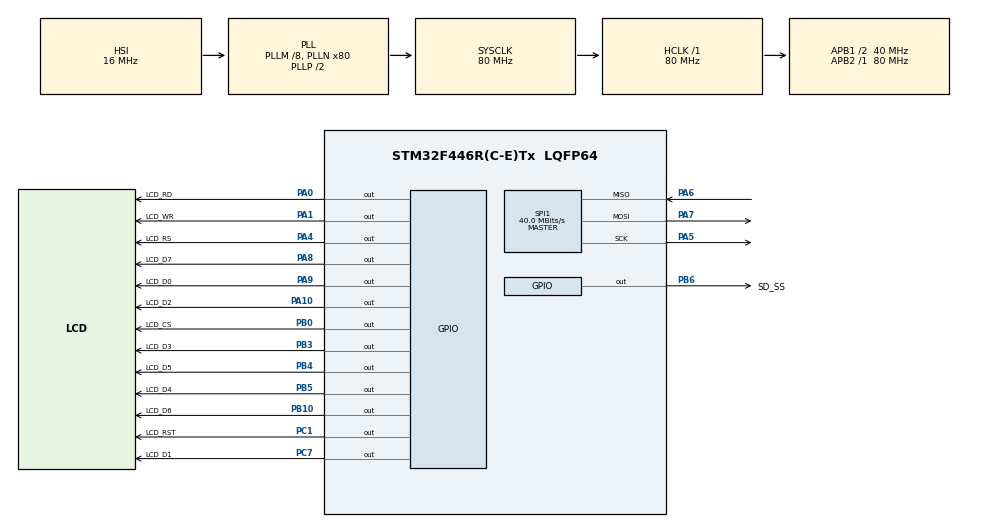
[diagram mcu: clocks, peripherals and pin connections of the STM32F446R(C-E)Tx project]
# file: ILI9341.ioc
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Mcu.Family=STM32F4
Mcu.Name=STM32F446R(C-E)Tx
Mcu.Package=LQFP64
NVIC.PriorityGroup=NVIC_PRIORITYGROUP_4
PA0-WKUP.GPIO_Label=LCD_RD
PA0-WKUP.GPIO_Speed=GPIO_SPEED_FREQ_HIGH
PA0-WKUP.Signal=GPIO_Output
PA1.GPIO_Label=LCD_WR
PA1.GPIO_Speed=GPIO_SPEED_FREQ_HIGH
PA1.Signal=GPIO_Output
PA10.GPIO_Label=LCD_D2
PA10.GPIO_Speed=GPIO_SPEED_FREQ_HIGH
PA10.Signal=GPIO_Output
PA13.Mode=Serial_Wire
PA13.Signal=SYS_JTMS-SWDIO
PA14.Mode=Serial_Wire
PA14.Signal=SYS_JTCK-SWCLK
PA4.GPIO_Label=LCD_RS
PA4.GPIO_Speed=GPIO_SPEED_FREQ_HIGH
PA4.Signal=GPIO_Output
PA5.Mode=Full_Duplex_Master
PA5.Signal=SPI1_SCK
PA6.Mode=Full_Duplex_Master
PA6.Signal=SPI1_MISO
PA7.Mode=Full_Duplex_Master
PA7.Signal=SPI1_MOSI
PA8.GPIO_Label=LCD_D7
PA8.GPIO_Speed=GPIO_SPEED_FREQ_HIGH
PA8.Signal=GPIO_Output
PA9.GPIO_Label=LCD_D0
PA9.GPIO_Speed=GPIO_SPEED_FREQ_HIGH
PA9.Signal=GPIO_Output
PB0.GPIO_Label=LCD_CS
PB0.GPIO_Speed=GPIO_SPEED_FREQ_HIGH
PB0.Signal=GPIO_Output
PB10.GPIO_Label=LCD_D6
PB10.GPIO_Speed=GPIO_SPEED_FREQ_HIGH
PB10.Signal=GPIO_Output
PB3.GPIO_Label=LCD_D3
PB3.GPIO_Speed=GPIO_SPEED_FREQ_HIGH
PB3.Signal=GPIO_Output
PB4.GPIO_Label=LCD_D5
PB4.GPIO_Speed=GPIO_SPEED_FREQ_HIGH
PB4.Signal=GPIO_Output
PB5.GPIO_Label=LCD_D4
PB5.GPIO_Speed=GPIO_SPEED_FREQ_HIGH
PB5.Signal=GPIO_Output
PB6.GPIO_Label=SD_SS
PB6.GPIO_Speed=GPIO_SPEED_FREQ_HIGH
PB6.Signal=GPIO_Output
PC1.GPIO_Label=LCD_RST
PC1.GPIO_Speed=GPIO_SPEED_FREQ_HIGH
PC1.Signal=GPIO_Output
PC7.GPIO_Label=LCD_D1
PC7.GPIO_Speed=GPIO_SPEED_FREQ_HIGH
PC7.Signal=GPIO_Output
PH0-OSC_IN.Mode=HSE-External-Oscillator
PH0-OSC_IN.Signal=RCC_OSC_IN
PH1-OSC_OUT.Mode=HSE-External-Oscillator
PH1-OSC_OUT.Signal=RCC_OSC_OUT
ProjectManager.HeapSize=0x200
ProjectManager.StackSize=0x400
ProjectManager.TargetToolchain=STM32CubeIDE
RCC.AHBFreq_Value=80000000
RCC.APB1CLKDivider=RCC_HCLK_DIV2
RCC.APB1Freq_Value=40000000
RCC.APB1TimFreq_Value=80000000
RCC.APB2Freq_Value=80000000
RCC.APB2TimFreq_Value=80000000
RCC.CortexFreq_Value=80000000
RCC.HCLKFreq_Value=80000000
RCC.PLLM=8
RCC.PLLN=80
RCC.SYSCLKFreq_VALUE=80000000
RCC.SYSCLKSource=RCC_SYSCLKSOURCE_PLLCLK
RCC.USBFreq_Value=80000000
RCC.VCOOutputFreq_Value=160000000
SPI1.CalculateBaudRate=40.0 MBits/s
SPI1.Direction=SPI_DIRECTION_2LINES
SPI1.Mode=SPI_MODE_MASTER
SPI1.VirtualType=VM_MASTER
board=custom

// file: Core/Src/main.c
/* USER CODE BEGIN Header */
/**
 ******************************************************************************
 * @file           : main.c
 * @brief          : Main program body
 ******************************************************************************
 * @attention
 *
 * Copyright (c) 2024 STMicroelectronics.
 * All rights reserved.
 *
 * This software is licensed under terms that can be found in the LICENSE file
 * in the root directory of this software component.
 * If no LICENSE file comes with this software, it is provided AS-IS.
 *
 ******************************************************************************
 */
/* USER CODE END Header */
#include "main.h"

/* USER CODE BEGIN Includes */
#include "ili9341.h"
/* USER CODE END Includes */

SPI_HandleTypeDef hspi1;
/* USER CODE BEGIN PV */
extern uint8_t fondo[];
/* USER CODE END PV */

void SystemClock_Config(void);
static void MX_GPIO_Init(void);
static void MX_SPI1_Init(void);

int main(void)
{

  /* MCU Configuration--------------------------------------------------------*/

  /* Reset of all peripherals, Initializes the Flash interface and the Systick. */
  HAL_Init();

  /* Configure the system clock */
  SystemClock_Config();

  /* Initialize all configured peripherals */
  MX_GPIO_Init();
  MX_SPI1_Init();
  /* USER CODE BEGIN 2 */

	LCD_Init();

	LCD_Clear(0x00);
	FillRect(0, 0, 319, 239, 0xFFFF);
	FillRect(50, 60, 20, 20, 0xF800);
	FillRect(70, 60, 20, 20, 0x07E0);
	FillRect(90, 60, 20, 20, 0x001F);

	//LCD_Bitmap(0, 0, 320, 240, fondo);
	 FillRect(0, 0, 319, 206, 0x1911);

	  LCD_Print("Hola Mundo", 20, 100, 1, 0x001F, 0xCAB9);

  /* USER CODE END 2 */

  /* Infinite loop */
	while (1) {

	}
}

void SystemClock_Config(void)
{
  RCC_OscInitTypeDef RCC_OscInitStruct = {0};
  RCC_ClkInitTypeDef RCC_ClkInitStruct = {0};

  /** Configure the main internal regulator output voltage
  */
  __HAL_RCC_PWR_CLK_ENABLE();
  __HAL_PWR_VOLTAGESCALING_CONFIG(PWR_REGULATOR_VOLTAGE_SCALE3);

  /** Initializes the RCC Oscillators according to the specified parameters
  * in the RCC_OscInitTypeDef structure.
  */
  RCC_OscInitStruct.OscillatorType = RCC_OSCILLATORTYPE_HSI;
  RCC_OscInitStruct.HSIState = RCC_HSI_ON;
  RCC_OscInitStruct.HSICalibrationValue = RCC_HSICALIBRATION_DEFAULT;
  RCC_OscInitStruct.PLL.PLLState = RCC_PLL_ON;
  RCC_OscInitStruct.PLL.PLLSource = RCC_PLLSOURCE_HSI;
  RCC_OscInitStruct.PLL.PLLM = 8;
  RCC_OscInitStruct.PLL.PLLN = 80;
  RCC_OscInitStruct.PLL.PLLP = RCC_PLLP_DIV2;
  RCC_OscInitStruct.PLL.PLLQ = 2;
  RCC_OscInitStruct.PLL.PLLR = 2;
  if (HAL_RCC_OscConfig(&RCC_OscInitStruct) != HAL_OK)
  {
    Error_Handler();
  }

  /** Initializes the CPU, AHB and APB buses clocks
  */
  RCC_ClkInitStruct.ClockType = RCC_CLOCKTYPE_HCLK|RCC_CLOCKTYPE_SYSCLK
                              |RCC_CLOCKTYPE_PCLK1|RCC_CLOCKTYPE_PCLK2;
  RCC_ClkInitStruct.SYSCLKSource = RCC_SYSCLKSOURCE_PLLCLK;
  RCC_ClkInitStruct.AHBCLKDivider = RCC_SYSCLK_DIV1;
  RCC_ClkInitStruct.APB1CLKDivider = RCC_HCLK_DIV2;
  RCC_ClkInitStruct.APB2CLKDivider = RCC_HCLK_DIV1;

  if (HAL_RCC_ClockConfig(&RCC_ClkInitStruct, FLASH_LATENCY_2) != HAL_OK)
  {
    Error_Handler();
  }
}

static void MX_SPI1_Init(void)
{

  /* SPI1 parameter configuration*/
  hspi1.Instance = SPI1;
  hspi1.Init.Mode = SPI_MODE_MASTER;
  hspi1.Init.Direction = SPI_DIRECTION_2LINES;
  hspi1.Init.DataSize = SPI_DATASIZE_8BIT;
  hspi1.Init.CLKPolarity = SPI_POLARITY_LOW;
  hspi1.Init.CLKPhase = SPI_PHASE_1EDGE;
  hspi1.Init.NSS = SPI_NSS_SOFT;
  hspi1.Init.BaudRatePrescaler = SPI_BAUDRATEPRESCALER_2;
  hspi1.Init.FirstBit = SPI_FIRSTBIT_MSB;
  hspi1.Init.TIMode = SPI_TIMODE_DISABLE;
  hspi1.Init.CRCCalculation = SPI_CRCCALCULATION_DISABLE;
  hspi1.Init.CRCPolynomial = 10;
  if (HAL_SPI_Init(&hspi1) != HAL_OK)
  {
    Error_Handler();
  }

}

static void MX_GPIO_Init(void)
{
  GPIO_InitTypeDef GPIO_InitStruct = {0};

  /* GPIO Ports Clock Enable */
  __HAL_RCC_GPIOH_CLK_ENABLE();
  __HAL_RCC_GPIOC_CLK_ENABLE();
  __HAL_RCC_GPIOA_CLK_ENABLE();
  __HAL_RCC_GPIOB_CLK_ENABLE();

  /*Configure GPIO pin Output Level */
  HAL_GPIO_WritePin(GPIOC, LCD_RST_Pin|LCD_D1_Pin, GPIO_PIN_RESET);

  /*Configure GPIO pin Output Level */
  HAL_GPIO_WritePin(GPIOA, LCD_RD_Pin|LCD_WR_Pin|LCD_RS_Pin|LCD_D7_Pin
                          |LCD_D0_Pin|LCD_D2_Pin, GPIO_PIN_RESET);

  /*Configure GPIO pin Output Level */
  HAL_GPIO_WritePin(GPIOB, LCD_CS_Pin|LCD_D6_Pin|LCD_D3_Pin|LCD_D5_Pin
                          |LCD_D4_Pin|SD_SS_Pin, GPIO_PIN_RESET);

  /*Configure GPIO pins : LCD_RST_Pin LCD_D1_Pin */
  GPIO_InitStruct.Pin = LCD_RST_Pin|LCD_D1_Pin;
  GPIO_InitStruct.Mode = GPIO_MODE_OUTPUT_PP;
  GPIO_InitStruct.Pull = GPIO_NOPULL;
  GPIO_InitStruct.Speed = GPIO_SPEED_FREQ_HIGH;
  HAL_GPIO_Init(GPIOC, &GPIO_InitStruct);

  /*Configure GPIO pins : LCD_RD_Pin LCD_WR_Pin LCD_RS_Pin LCD_D7_Pin
                           LCD_D0_Pin LCD_D2_Pin */
  GPIO_InitStruct.Pin = LCD_RD_Pin|LCD_WR_Pin|LCD_RS_Pin|LCD_D7_Pin
                          |LCD_D0_Pin|LCD_D2_Pin;
  GPIO_InitStruct.Mode = GPIO_MODE_OUTPUT_PP;
  GPIO_InitStruct.Pull = GPIO_NOPULL;
  GPIO_InitStruct.Speed = GPIO_SPEED_FREQ_HIGH;
  HAL_GPIO_Init(GPIOA, &GPIO_InitStruct);

  /*Configure GPIO pins : LCD_CS_Pin LCD_D6_Pin LCD_D3_Pin LCD_D5_Pin
                           LCD_D4_Pin SD_SS_Pin */
  GPIO_InitStruct.Pin = LCD_CS_Pin|LCD_D6_Pin|LCD_D3_Pin|LCD_D5_Pin
                          |LCD_D4_Pin|SD_SS_Pin;
  GPIO_InitStruct.Mode = GPIO_MODE_OUTPUT_PP;
  GPIO_InitStruct.Pull = GPIO_NOPULL;
  GPIO_InitStruct.Speed = GPIO_SPEED_FREQ_HIGH;
  HAL_GPIO_Init(GPIOB, &GPIO_InitStruct);

}

void Error_Handler(void)
{
	__disable_irq();
	while (1) {
	}
}
